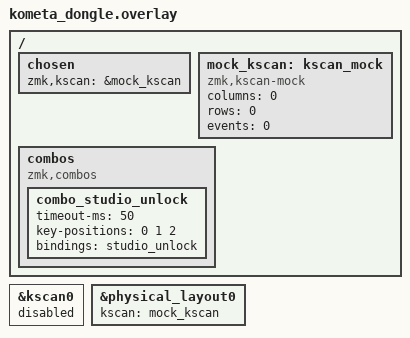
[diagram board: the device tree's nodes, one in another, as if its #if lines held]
#include "kometa.dtsi"

/ {
    chosen {
        zmk,kscan = &mock_kscan;
    };

    mock_kscan: kscan_mock {
        compatible = "zmk,kscan-mock";
        columns = <0>;
        rows = <0>;
        events = <0>;
    };
};

// The dongle has no GPIO matrix. Keep the shared 42-key layout and transform.
&kscan0 {
    status = "disabled";
};

&physical_layout0 {
    kscan = <&mock_kscan>;
};

// Keep conditional Studio configuration outside the keymap for Keymap Editor.
/ {
#ifdef CONFIG_ZMK_STUDIO
    combos {
        compatible = "zmk,combos";

        combo_studio_unlock {
            timeout-ms = <50>;
            key-positions = <0 1 2>;
            bindings = <&studio_unlock>;
        };
    };
#endif
};
